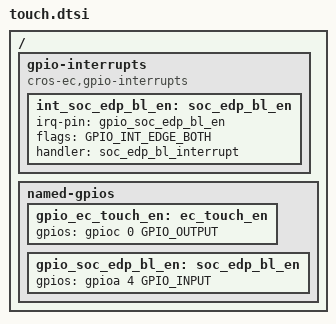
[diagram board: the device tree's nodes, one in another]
/* Copyright 2024 The ChromiumOS Authors
 * Use of this source code is governed by a BSD-style license that can be
 * found in the LICENSE file.
 */

#include "../baseboard/baseboard.overlay"
#include "../program/brox/jubilant/cbi.dtsi"

/ {
	gpio-interrupts {
		compatible = "cros-ec,gpio-interrupts";
		int_soc_edp_bl_en: soc_edp_bl_en {
			irq-pin = <&gpio_soc_edp_bl_en>;
			flags = <GPIO_INT_EDGE_BOTH>;
			handler = "soc_edp_bl_interrupt";
		};
	};
	named-gpios {
		/delete-node/ bat_disconnect_ec_odl;
		gpio_ec_touch_en: ec_touch_en {
			gpios = <&gpioc 0 GPIO_OUTPUT>;
		};
		gpio_soc_edp_bl_en: soc_edp_bl_en {
			gpios = <&gpioa 4 GPIO_INPUT>;
		};
	};
};
